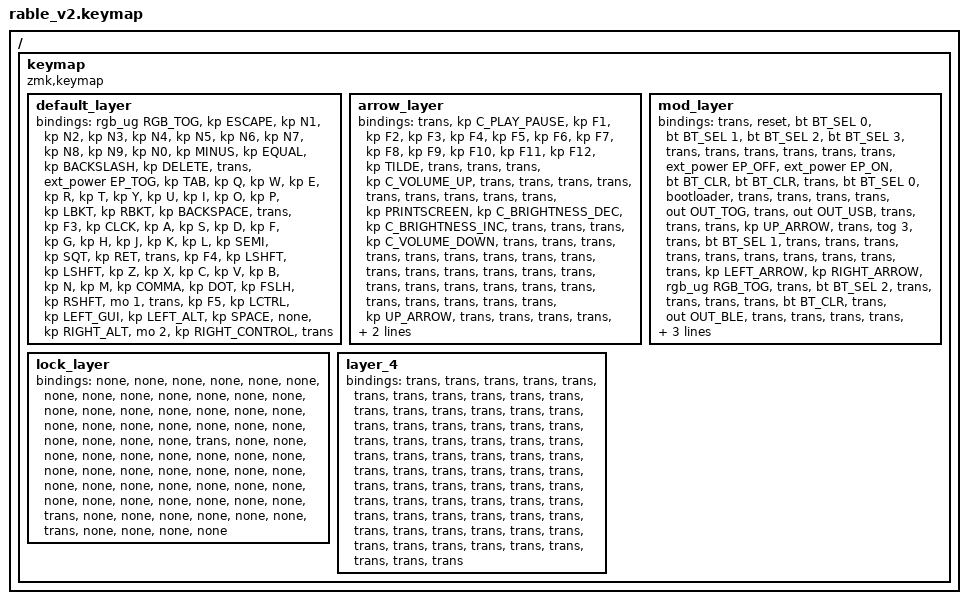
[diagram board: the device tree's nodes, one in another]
/*
 * Copyright (c) 2021 Nick Winans
 *
 * SPDX-License-Identifier: MIT
 */

#include <behaviors.dtsi>
#include <dt-bindings/zmk/bt.h>
#include <dt-bindings/zmk/ext_power.h>
#include <dt-bindings/zmk/keys.h>
#include <dt-bindings/zmk/outputs.h>
#include <dt-bindings/zmk/rgb.h>

/ {
    keymap {
        compatible = "zmk,keymap";

        default_layer {
            bindings = <
&rgb_ug RGB_TOG  &kp ESCAPE  &kp N1  &kp N2  &kp N3  &kp N4  &kp N5  &kp N6  &kp N7  &kp N8  &kp N9  &kp N0  &kp MINUS  &kp EQUAL  &kp BACKSLASH  &kp DELETE  &trans  &ext_power EP_TOG  &kp TAB  &kp Q  &kp W  &kp E  &kp R  &kp T  &kp Y  &kp U  &kp I  &kp O  &kp P  &kp LBKT  &kp RBKT  &kp BACKSPACE  &trans  &kp F3  &kp CLCK  &kp A  &kp S  &kp D  &kp F  &kp G  &kp H  &kp J  &kp K  &kp L  &kp SEMI  &kp SQT  &kp RET  &trans  &kp F4  &kp LSHFT  &kp LSHFT  &kp Z  &kp X  &kp C  &kp V  &kp B  &kp N  &kp M  &kp COMMA  &kp DOT  &kp FSLH  &kp RSHFT  &mo 1  &trans  &kp F5  &kp LCTRL  &kp LEFT_GUI  &kp LEFT_ALT  &kp SPACE  &none  &kp RIGHT_ALT  &mo 2  &kp RIGHT_CONTROL  &trans
            >;
        };

        arrow_layer {
            bindings = <
&trans  &kp C_PLAY_PAUSE  &kp F1  &kp F2  &kp F3  &kp F4  &kp F5  &kp F6  &kp F7  &kp F8  &kp F9  &kp F10  &kp F11  &kp F12  &kp TILDE  &trans  &trans  &trans  &kp C_VOLUME_UP  &trans  &trans  &trans  &trans  &trans  &trans  &trans  &trans  &trans  &kp PRINTSCREEN  &kp C_BRIGHTNESS_DEC  &kp C_BRIGHTNESS_INC  &trans  &trans  &trans  &kp C_VOLUME_DOWN  &trans  &trans  &trans  &trans  &trans  &trans  &trans  &trans  &trans  &trans  &trans  &trans  &trans  &trans  &trans  &trans  &trans  &trans  &trans  &trans  &trans  &trans  &trans  &trans  &trans  &trans  &kp UP_ARROW  &trans  &trans  &trans  &trans  &trans  &trans  &trans  &trans  &kp LEFT  &kp DOWN  &kp RIGHT  &trans
            >;
        };

        mod_layer {
            bindings = <
&trans  &reset  &bt BT_SEL 0  &bt BT_SEL 1  &bt BT_SEL 2  &bt BT_SEL 3  &trans  &trans  &trans  &trans  &trans  &trans  &ext_power EP_OFF  &ext_power EP_ON  &bt BT_CLR  &bt BT_CLR  &trans  &bt BT_SEL 0  &bootloader  &trans  &trans  &trans  &trans  &out OUT_TOG  &trans  &out OUT_USB  &trans  &trans  &trans  &kp UP_ARROW  &trans  &tog 3  &trans  &bt BT_SEL 1  &trans  &trans  &trans  &trans  &trans  &trans  &trans  &trans  &trans  &trans  &kp LEFT_ARROW  &kp RIGHT_ARROW  &rgb_ug RGB_TOG  &trans  &bt BT_SEL 2  &trans  &trans  &trans  &trans  &bt BT_CLR  &trans  &out OUT_BLE  &trans  &trans  &trans  &trans  &kp DOWN_ARROW  &trans  &trans  &trans  &bt BT_SEL 3  &trans  &trans  &trans  &trans  &trans  &trans  &trans  &trans  &trans
            >;
        };

        lock_layer {
            bindings = <
&none  &none  &none  &none  &none  &none  &none  &none  &none  &none  &none  &none  &none  &none  &none  &none  &none  &none  &none  &none  &none  &none  &none  &none  &none  &none  &none  &none  &none  &none  &none  &trans  &none  &none  &none  &none  &none  &none  &none  &none  &none  &none  &none  &none  &none  &none  &none  &none  &none  &none  &none  &none  &none  &none  &none  &none  &none  &none  &none  &none  &none  &none  &trans  &none  &none  &none  &none  &none  &none  &trans  &none  &none  &none  &none
            >;
        };

        layer_4 {
            bindings = <
&trans  &trans  &trans  &trans  &trans  &trans  &trans  &trans  &trans  &trans  &trans  &trans  &trans  &trans  &trans  &trans  &trans  &trans  &trans  &trans  &trans  &trans  &trans  &trans  &trans  &trans  &trans  &trans  &trans  &trans  &trans  &trans  &trans  &trans  &trans  &trans  &trans  &trans  &trans  &trans  &trans  &trans  &trans  &trans  &trans  &trans  &trans  &trans  &trans  &trans  &trans  &trans  &trans  &trans  &trans  &trans  &trans  &trans  &trans  &trans  &trans  &trans  &trans  &trans  &trans  &trans  &trans  &trans  &trans  &trans  &trans  &trans  &trans  &trans
            >;
        };
    };
};
